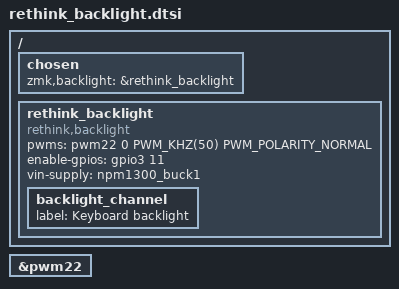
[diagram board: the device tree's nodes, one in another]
/*
 * Copyright (c) 2026 Ziemniaczenka
 * SPDX-License-Identifier: MIT
 *
 * Keyboard backlight: VLED_BL (P3.11) -> adapter boost (BOOST_EN) -> PWM on
 * P1.17. Include after rethink_adapter.dtsi, for keyboards that may have a
 * backlight: it stays locked unless KBD_BL_DTCT reads a backlit keyboard.
 * Supply source and duty cycle limit: config/rethink.conf.
 */

#include <zephyr/dt-bindings/pwm/pwm.h>

/ {
    chosen {
        zmk,backlight = &rethink_backlight;
    };

    // 50 kHz. On the E580 4096 Hz whined, with VLED_BL dips of 0.5 V once
    // per period; 25 kHz still whined faintly at the low step; 50 kHz is
    // silent ("backlight khz" tries others).
    rethink_backlight: rethink_backlight {
        compatible = "rethink,backlight";
        pwms = <&pwm22 0 PWM_KHZ(50) PWM_POLARITY_NORMAL>;
        enable-gpios = <&gpio3 11 GPIO_ACTIVE_HIGH>;
        vin-supply = <&npm1300_buck1>;

        backlight_channel {
            label = "Keyboard backlight";
        };
    };
};

&pwm22 {
    status = "okay";
};
